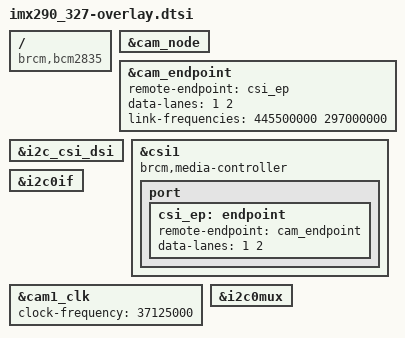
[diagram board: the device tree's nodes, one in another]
// SPDX-License-Identifier: GPL-2.0-only
// Partial definitions for IMX290 or IMX327 camera module on VC I2C bus
// The compatible string should be set in an overlay that then includes this one
/dts-v1/;
/plugin/;

#include <dt-bindings/gpio/gpio.h>

/{
	compatible = "brcm,bcm2835";

	i2c_frag: fragment@0 {
		target = <&i2c_csi_dsi>;
		__overlay__ {
			#address-cells = <1>;
			#size-cells = <0>;
			status = "okay";

			#include "imx290_327.dtsi"
		};
	};

	csi_frag: fragment@1 {
		target = <&csi1>;
		csi: __overlay__ {
			status = "okay";
			brcm,media-controller;

			port {
				csi_ep: endpoint {
					remote-endpoint = <&cam_endpoint>;
				};
			};
		};
	};

	fragment@2 {
		target = <&i2c0if>;
		__overlay__ {
			status = "okay";
		};
	};

	clk_frag: fragment@3 {
		target = <&cam1_clk>;
		cam_clk: __overlay__ {
			status = "okay";
			clock-frequency = <37125000>;
		};
	};

	fragment@4 {
		target = <&i2c0mux>;
		__overlay__ {
			status = "okay";
		};
	};

	fragment@6 {
		target = <&cam_endpoint>;
		__overlay__ {
			data-lanes = <1 2>;
			link-frequencies =
				/bits/ 64 <445500000 297000000>;
		};
	};

	fragment@7 {
		target = <&cam_endpoint>;
		__dormant__ {
			data-lanes = <1 2 3 4>;
			link-frequencies =
				/bits/ 64 <222750000 148500000>;
		};
	};

	fragment@8 {
		target = <&csi_ep>;
		__overlay__ {
			data-lanes = <1 2>;
		};
	};

	fragment@9 {
		target = <&csi_ep>;
		__dormant__ {
			data-lanes = <1 2 3 4>;
		};
	};

	__overrides__ {
		4lane = <0>, "-6+7-8+9";
		clock-frequency = <&cam_clk>,"clock-frequency:0",
				  <&cam_node>,"clock-frequency:0";
		rotation = <&cam_node>,"rotation:0";
		orientation = <&cam_node>,"orientation:0";
		media-controller = <&csi>,"brcm,media-controller?";
		cam0 = <&i2c_frag>, "target:0=",<&i2c_csi_dsi0>,
		       <&csi_frag>, "target:0=",<&csi0>,
		       <&clk_frag>, "target:0=",<&cam0_clk>,
		       <&cam_node>, "clocks:0=",<&cam0_clk>,
		       <&cam_node>, "vdda-supply:0=",<&cam0_reg>;
	};
};

&cam_node {
	status = "okay";
};

&cam_endpoint {
	remote-endpoint = <&csi_ep>;
};
